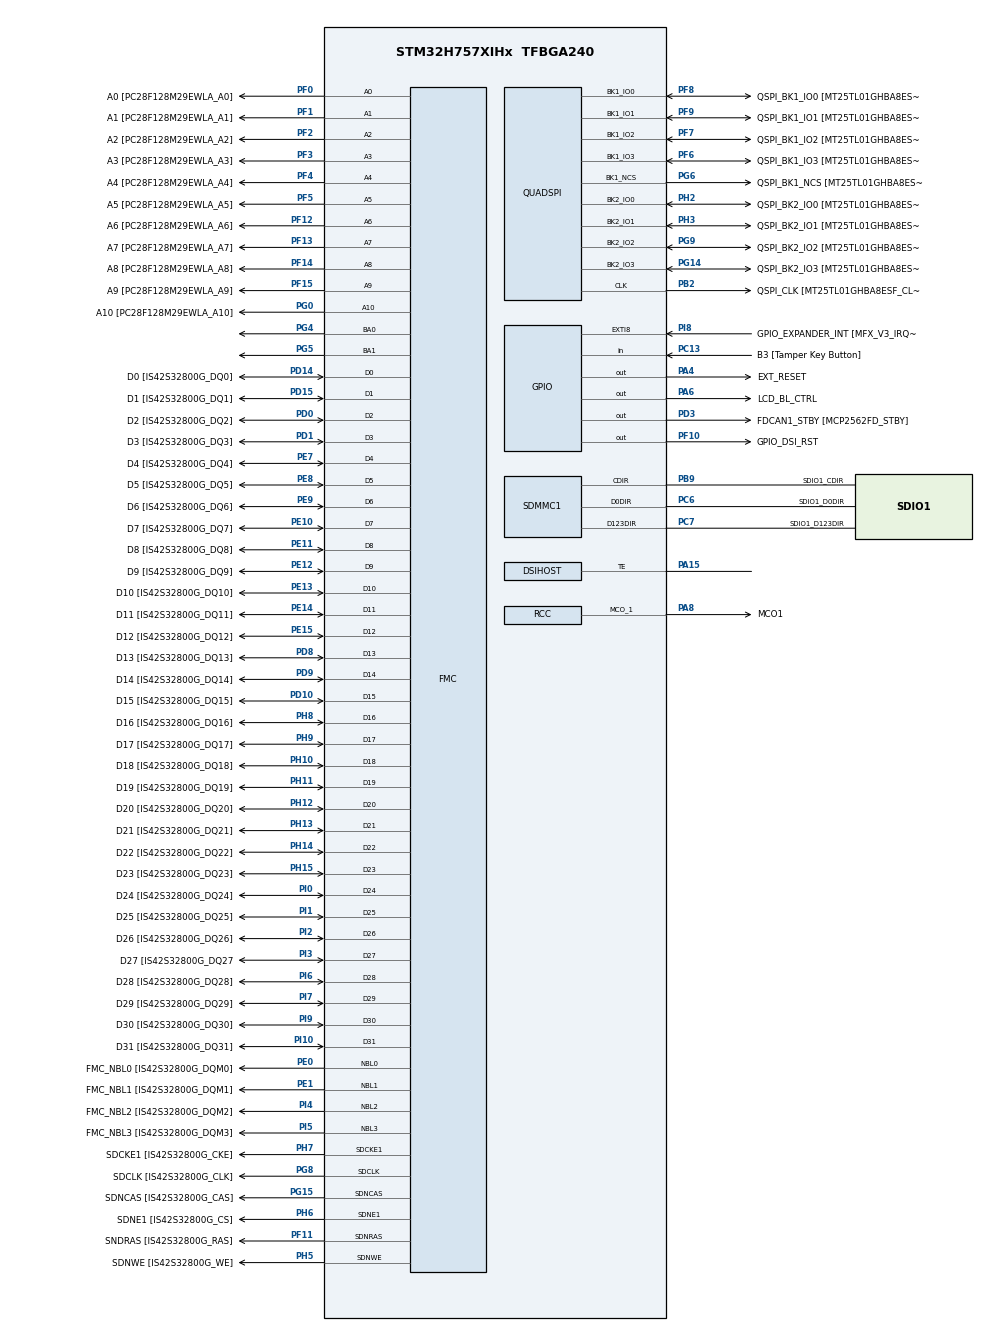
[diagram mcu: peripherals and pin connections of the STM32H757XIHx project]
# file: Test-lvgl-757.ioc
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CortexM4.IPs=FATFS_M4\:I,FREERTOS_M4\:I,IWDG2\:I,RCC,USB_DEVICE_M4\:I,USB_HOST_M4\:I,WWDG2\:I,DMA,BDMA,MDMA,NVIC2\:I,DEBUG,PDM2PCM_M4\:I,PWR,RESMGR_UTILITY,SYS_M4\:I,CORTEX_M4\:I,OPENAMP_M4\:I,VREFBUF
CortexM7.IPs=FATFS_M7\:I,FREERTOS_M7\:I,IWDG1\:I,RCC\:I,USB_DEVICE_M7\:I,USB_HOST_M7\:I,WWDG1\:I,DMA\:I,BDMA\:I,MDMA\:I,NVIC1\:I,FMC\:I,LTDC\:I,DSIHOST\:I,QUADSPI\:I,SYS\:I,CORTEX_M7\:I,DEBUG\:I,PDM2PCM_M7\:I,PWR\:I,RESMGR_UTILITY\:I,OPENAMP_M7\:I,VREFBUF\:I,DMA2D\:I,RTC\:I,TIM2\:I
DMA2D.Mode=DMA2D_R2M
DSIHOST.AcknowledgeRequest=DSI_ACKNOWLEDGE_ENABLE
DSIHOST.AutomaticRefresh=DSI_AR_DISABLE
DSIHOST.CommandSize=800
DSIHOST.LPDcsLongWrite=DSI_LP_DLW_ENABLE
DSIHOST.LPDcsShortReadNoP=DSI_LP_DSR0P_ENABLE
DSIHOST.LPDcsShortWriteNoP=DSI_LP_DSW0P_ENABLE
DSIHOST.LPDcsShortWriteOneP=DSI_LP_DSW1P_ENABLE
DSIHOST.LPGenLongWrite=DSI_LP_GLW_ENABLE
DSIHOST.LPGenShortReadNoP=DSI_LP_GSR0P_ENABLE
DSIHOST.LPGenShortReadOneP=DSI_LP_GSR1P_ENABLE
DSIHOST.LPGenShortReadTwoP=DSI_LP_GSR2P_ENABLE
DSIHOST.LPGenShortWriteNoP=DSI_LP_GSW0P_ENABLE
DSIHOST.LPGenShortWriteOneP=DSI_LP_GSW1P_ENABLE
DSIHOST.LPGenShortWriteTwoP=DSI_LP_GSW2P_ENABLE
DSIHOST.LPMaxReadPacket=DSI_LP_MRDP_ENABLE
DSIHOST.LowPowerReceptionTimeout=0
DSIHOST.NumberOfLanes=DSI_TWO_DATA_LANES
DSIHOST.TEAcknowledgeRequest=DSI_TE_ACKNOWLEDGE_ENABLE
DSI_CKN.Mode=DSIHost_Adapted_TE
DSI_CKN.PinAttribute=CortexM7
DSI_CKN.Signal=DSIHOST_CKN
DSI_CKP.Mode=DSIHost_Adapted_TE
DSI_CKP.PinAttribute=CortexM7
DSI_CKP.Signal=DSIHOST_CKP
DSI_D0N.Mode=DSIHost_Adapted_TE
DSI_D0N.PinAttribute=CortexM7
DSI_D0N.Signal=DSIHOST_D0N
DSI_D0P.Mode=DSIHost_Adapted_TE
DSI_D0P.PinAttribute=CortexM7
DSI_D0P.Signal=DSIHOST_D0P
DSI_D1N.Mode=DSIHost_Adapted_TE
DSI_D1N.PinAttribute=CortexM7
DSI_D1N.Signal=DSIHOST_D1N
DSI_D1P.Mode=DSIHost_Adapted_TE
DSI_D1P.PinAttribute=CortexM7
DSI_D1P.Signal=DSIHOST_D1P
Dma.MEMTOMEM.0.Direction=DMA_MEMORY_TO_MEMORY
Dma.MEMTOMEM.0.EventEnable=DISABLE
Dma.MEMTOMEM.0.FIFOMode=DMA_FIFOMODE_ENABLE
Dma.MEMTOMEM.0.FIFOThreshold=DMA_FIFO_THRESHOLD_1QUARTERFULL
Dma.MEMTOMEM.0.Instance=DMA2_Stream0
Dma.MEMTOMEM.0.MemBurst=DMA_MBURST_SINGLE
Dma.MEMTOMEM.0.MemDataAlignment=DMA_MDATAALIGN_HALFWORD
Dma.MEMTOMEM.0.MemInc=DMA_MINC_ENABLE
Dma.MEMTOMEM.0.Mode=DMA_NORMAL
Dma.MEMTOMEM.0.PeriphBurst=DMA_PBURST_SINGLE
Dma.MEMTOMEM.0.PeriphDataAlignment=DMA_PDATAALIGN_HALFWORD
Dma.MEMTOMEM.0.PeriphInc=DMA_PINC_ENABLE
Dma.MEMTOMEM.0.Polarity=HAL_DMAMUX_REQ_GEN_RISING
Dma.MEMTOMEM.0.Priority=DMA_PRIORITY_HIGH
Dma.MEMTOMEM.0.RequestNumber=1
Dma.MEMTOMEM.0.SignalID=NONE
Dma.MEMTOMEM.0.SyncEnable=DISABLE
Dma.MEMTOMEM.0.SyncPolarity=HAL_DMAMUX_SYNC_NO_EVENT
Dma.MEMTOMEM.0.SyncRequestNumber=1
Dma.MEMTOMEM.0.SyncSignalID=NONE
Dma.Request0=MEMTOMEM
LTDC.ActiveW=800
LTDC.Alpha_L0=255
LTDC.BlendingFactor1_L0=LTDC_BLENDING_FACTOR1_PAxCA
LTDC.BlendingFactor2_L0=LTDC_BLENDING_FACTOR2_PAxCA
LTDC.Blue_L0=20
LTDC.FBStartAdress_L0=0xD0000000
LTDC.Green_L0=40
LTDC.HBP=2
LTDC.HFP=1
LTDC.HSPolarity=LTDC_HSPOLARITY_AH
LTDC.HSync=1
LTDC.ImageHeight_L0=480
LTDC.ImageWidth_L0=800
LTDC.Layers=0
LTDC.PixelFormat_L0=LTDC_PIXEL_FORMAT_RGB565
LTDC.Red_L0=60
LTDC.VFP=1
LTDC.VSPolarity=LTDC_VSPOLARITY_AH
LTDC.VSync=1
LTDC.WindowX1_L0=800
LTDC.WindowY1_L0=480
Mcu.Family=STM32H7
Mcu.Name=STM32H757XIHx
Mcu.Package=TFBGA240
NVIC1.DMA2D_IRQn=true\:0\:0\:false\:false\:true\:true\:true
NVIC1.DSI_IRQn=true\:0\:0\:false\:false\:true\:true\:true
NVIC1.LTDC_IRQn=true\:0\:0\:false\:false\:true\:true\:true
NVIC1.PriorityGroup=NVIC_PRIORITYGROUP_4
NVIC1.TIM2_IRQn=true\:0\:0\:false\:false\:true\:true\:true
NVIC2.PriorityGroup=NVIC_PRIORITYGROUP_4
PA1.GPIO_Label=RMII_REF_CLK [LAN8742A_REFCLK0]
PA1.PinAttribute=CortexM4
PA1.Signal=ETH_REF_CLK
PA11.GPIO_Label=USB_FS2_DM
PA11.PinAttribute=CortexM7
PA11.Signal=USB_OTG_FS_DM
PA12.GPIO_Label=USB_FS2_DP
PA12.PinAttribute=CortexM7
PA12.Signal=USB_OTG_FS_DP
PA15\ (JTDI).Mode=DSIHost_Adapted_TE
PA15\ (JTDI).PinAttribute=CortexM7
PA15\ (JTDI).Signal=DSIHOST_TE
PA2.GPIO_Label=RMII_MDIO [LAN8742A_MDIO]
PA2.PinAttribute=CortexM4
PA2.Signal=ETH_MDIO
PA3.GPIO_Label=ULPI_D0 [USB3320C_D0]
PA3.PinAttribute=CortexM7
PA3.Signal=USB_OTG_HS_ULPI_D0
PA4.GPIO_Label=EXT_RESET
PA4.PinAttribute=Free
PA4.Signal=GPIO_Output
PA5.GPIO_Label=ULPI_CK  [USB3320C_CLKOUT]
PA5.PinAttribute=CortexM7
PA5.Signal=USB_OTG_HS_ULPI_CK
PA6.GPIO_Label=LCD_BL_CTRL
PA6.PinAttribute=Free
PA6.Signal=GPIO_Output
PA7.GPIO_Label=RMII_CRS_DV [LAN8742A_CRS_DV]
PA7.PinAttribute=CortexM4
PA7.Signal=ETH_CRS_DV
PA8.GPIO_Label=MCO1
PA8.Mode=Clock-out-1
PA8.PinAttribute=CortexM7
PA8.Signal=RCC_MCO_1
PA9.GPIO_Label=USB_FS2_VBUS
PA9.PinAttribute=CortexM7
PA9.Signal=USB_OTG_FS_VBUS
PB0.GPIO_Label=ULPI_D1 [USB3320C_D1]
PB0.PinAttribute=CortexM7
PB0.Signal=USB_OTG_HS_ULPI_D1
PB1.GPIO_Label=ULPI_D2 [USB3320C_D2]
PB1.PinAttribute=CortexM7
PB1.Signal=USB_OTG_HS_ULPI_D2
PB10.GPIO_Label=ULPI_D3 [USB3320C_D3]
PB10.PinAttribute=CortexM7
PB10.Signal=USB_OTG_HS_ULPI_D3
PB11.GPIO_Label=ULPI_D4 [USB3320C_D4]
PB11.PinAttribute=CortexM7
PB11.Signal=USB_OTG_HS_ULPI_D4
PB12.GPIO_Label=ULPI_D5 [USB3320C_D5]
PB12.PinAttribute=CortexM7
PB12.Signal=USB_OTG_HS_ULPI_D5
PB13.GPIO_Label=ULPI_D6 [USB3320C_D6]
PB13.PinAttribute=CortexM7
PB13.Signal=USB_OTG_HS_ULPI_D6
PB14.GPIO_Label=RS232_TX [ST3241EBPR_T2IN]
PB14.PinAttribute=CortexM4
PB14.Signal=USART1_TX
PB15.GPIO_Label=RS_232RX [ST3241EBPR_R3OUT]
PB15.PinAttribute=CortexM4
PB15.Signal=USART1_RX
PB2.GPIO_Label=QSPI_CLK [MT25TL01GHBA8ESF_CLK_1]
PB2.Mode=Dual_Bank
PB2.PinAttribute=CortexM7
PB2.Signal=QUADSPI_CLK
PB5.GPIO_Label=ULPI_D7 [USB3320C_D7]
PB5.PinAttribute=CortexM7
PB5.Signal=USB_OTG_HS_ULPI_D7
PB6.GPIO_Label=I2C1_SCL [STM32L152CCT6_I2C_SCL]
PB6.GPIO_Pu=GPIO_PULLUP
PB6.PinAttribute=CortexM4
PB6.Signal=I2C1_SCL
PB7.GPIO_Label=I2C1_SDA [STM32L152CCT6_I2C_SDA]
PB7.GPIO_Pu=GPIO_PULLUP
PB7.PinAttribute=CortexM4
PB7.Signal=I2C1_SDA
PB8.GPIO_Label=SDIO1_CKIN
PB8.PinAttribute=CortexM7
PB8.Signal=SDMMC1_CKIN
PB9.GPIO_Label=SDIO1_CDIR
PB9.Mode=SD_4_bits_Wide_bus_dir_voltage_converter
PB9.PinAttribute=CortexM7
PB9.Signal=SDMMC1_CDIR
PC0.GPIO_Label=ULPI_STP [USB3320C_STP]
PC0.PinAttribute=CortexM7
PC0.Signal=USB_OTG_HS_ULPI_STP
PC1.GPIO_Label=RMII_MDC [LAN8742A_MDC]
PC1.PinAttribute=CortexM4
PC1.Signal=ETH_MDC
PC10.GPIO_Label=SDIO1_D2
PC10.PinAttribute=CortexM7
PC10.Signal=SDMMC1_D2
PC11.GPIO_Label=SDIO1_D3
PC11.PinAttribute=CortexM7
PC11.Signal=SDMMC1_D3
PC12.GPIO_Label=SDIO1_CLK
PC12.PinAttribute=CortexM7
PC12.Signal=SDMMC1_CK
PC13.GPIO_Label=B3 [Tamper Key Button]
PC13.PinAttribute=Free
PC13.Signal=GPIO_Input
PC14-OSC32_IN\ (OSC32_IN).GPIO_Label=OSC32_IN
PC14-OSC32_IN\ (OSC32_IN).Mode=LSE-External-Oscillator
PC14-OSC32_IN\ (OSC32_IN).PinAttribute=CortexM7
PC14-OSC32_IN\ (OSC32_IN).Signal=RCC_OSC32_IN
PC15-OSC32_OUT\ (OSC32_OUT).GPIO_Label=OSC32_OUT
PC15-OSC32_OUT\ (OSC32_OUT).Mode=LSE-External-Oscillator
PC15-OSC32_OUT\ (OSC32_OUT).PinAttribute=CortexM7
PC15-OSC32_OUT\ (OSC32_OUT).Signal=RCC_OSC32_OUT
PC2.GPIO_Label=DFSDM_CLK
PC2.PinAttribute=CortexM7
PC2.Signal=S_CKOUTDFSDM1
PC3.GPIO_Label=DFSM_DAT1
PC3.PinAttribute=CortexM7
PC3.Signal=S_DATAIN1DFSDM1
PC4.GPIO_Label=RMII_RXD0 [LAN8742A_RXD0]
PC4.PinAttribute=CortexM4
PC4.Signal=ETH_RXD0
PC5.GPIO_Label=RMII_RXD1 [LAN8742A_RXD1]
PC5.PinAttribute=CortexM4
PC5.Signal=ETH_RXD1
PC6.GPIO_Label=SDIO1_D0DIR
PC6.Mode=SD_4_bits_Wide_bus_dir_voltage_converter
PC6.PinAttribute=CortexM7
PC6.Signal=SDMMC1_D0DIR
PC7.GPIO_Label=SDIO1_D123DIR
PC7.Mode=SD_4_bits_Wide_bus_dir_voltage_converter
PC7.PinAttribute=CortexM7
PC7.Signal=SDMMC1_D123DIR
PC8.GPIO_Label=SDIO1_D0
PC8.PinAttribute=CortexM7
PC8.Signal=SDMMC1_D0
PC9.GPIO_Label=SDIO1_D1
PC9.PinAttribute=CortexM7
PC9.Signal=SDMMC1_D1
PD0.GPIO_Label=D2 [IS42S32800G_DQ2]
PD0.PinAttribute=CortexM7
PD0.Signal=FMC_D2_DA2
PD1.GPIO_Label=D3 [IS42S32800G_DQ3]
PD1.PinAttribute=CortexM7
PD1.Signal=FMC_D3_DA3
PD10.GPIO_Label=D15 [IS42S32800G_DQ15]
PD10.PinAttribute=CortexM7
PD10.Signal=FMC_D15_DA15
PD11.GPIO_Label=A16 [PC28F128M29EWLA_A16]
PD11.PinAttribute=CortexM7
PD11.Signal=FMC_A16_CLE
PD12.GPIO_Label=A17 [PC28F128M29EWLA_A17]
PD12.PinAttribute=CortexM7
PD12.Signal=FMC_A17_ALE
PD13.GPIO_Label=A18 [PC28F128M29EWLA_A18]
PD13.PinAttribute=CortexM7
PD13.Signal=FMC_A18
PD14.GPIO_Label=D0 [IS42S32800G_DQ0]
PD14.PinAttribute=CortexM7
PD14.Signal=FMC_D0_DA0
PD15.GPIO_Label=D1 [IS42S32800G_DQ1]
PD15.PinAttribute=CortexM7
PD15.Signal=FMC_D1_DA1
PD2.GPIO_Label=SDIO1_CMD
PD2.PinAttribute=CortexM7
PD2.Signal=SDMMC1_CMD
PD3.GPIO_Label=FDCAN1_STBY [MCP2562FD_STBY]
PD3.PinAttribute=Free
PD3.Signal=GPIO_Output
PD4.GPIO_Label=FMC_NOE [IS61WV102416BLL_OE]
PD4.PinAttribute=CortexM7
PD4.Signal=FMC_NOE
PD5.GPIO_Label=FMC_NWE [IS61WV102416BLL_WE]
PD5.PinAttribute=CortexM7
PD5.Signal=FMC_NWE
PD6.GPIO_Label=FMC_NWAIT [PC28F128M29EWLA_RB]
PD6.PinAttribute=CortexM7
PD6.Signal=FMC_NWAIT
PD7.GPIO_Label=FMC_NE1 [PC28F128M29EWLA_E]
PD7.PinAttribute=CortexM7
PD7.Signal=FMC_NE1
PD8.GPIO_Label=D13 [IS42S32800G_DQ13]
PD8.PinAttribute=CortexM7
PD8.Signal=FMC_D13_DA13
PD9.GPIO_Label=D14 [IS42S32800G_DQ14]
PD9.PinAttribute=CortexM7
PD9.Signal=FMC_D14_DA14
PE0.GPIO_Label=FMC_NBL0 [IS42S32800G_DQM0]
PE0.PinAttribute=CortexM7
PE0.Signal=FMC_NBL0
PE1.GPIO_Label=FMC_NBL1 [IS42S32800G_DQM1]
PE1.PinAttribute=CortexM7
PE1.Signal=FMC_NBL1
PE10.GPIO_Label=D7 [IS42S32800G_DQ7]
PE10.PinAttribute=CortexM7
PE10.Signal=FMC_D7_DA7
PE11.GPIO_Label=D8 [IS42S32800G_DQ8]
PE11.PinAttribute=CortexM7
PE11.Signal=FMC_D8_DA8
PE12.GPIO_Label=D9 [IS42S32800G_DQ9]
PE12.PinAttribute=CortexM7
PE12.Signal=FMC_D9_DA9
PE13.GPIO_Label=D10 [IS42S32800G_DQ10]
PE13.PinAttribute=CortexM7
PE13.Signal=FMC_D10_DA10
PE14.GPIO_Label=D11 [IS42S32800G_DQ11]
PE14.PinAttribute=CortexM7
PE14.Signal=FMC_D11_DA11
PE15.GPIO_Label=D12 [IS42S32800G_DQ12]
PE15.PinAttribute=CortexM7
PE15.Signal=FMC_D12_DA12
PE2.GPIO_Label=PDM1_CLK
PE2.PinAttribute=CortexM7
PE2.Signal=SAI4_CK1
PE3.GPIO_Label=SAI1_SDB [WM8994ECS_ADCDAT1]
PE3.PinAttribute=CortexM7
PE3.Signal=SAI1_SD_B
PE4.GPIO_Label=SAI1_FSA [WM8994ECS_LRCLK1]
PE4.PinAttribute=CortexM7
PE4.Signal=SAI1_FS_A
PE5.GPIO_Label=SAI1_SCKA [WM8994ECS_BCK1]
PE5.PinAttribute=CortexM7
PE5.Signal=SAI1_SCK_A
PE6.GPIO_Label=SAI1_SDA [WM8994ECS_DACDAT1]
PE6.PinAttribute=CortexM7
PE6.Signal=SAI1_SD_A
PE7.GPIO_Label=D4 [IS42S32800G_DQ4]
PE7.PinAttribute=CortexM7
PE7.Signal=FMC_D4_DA4
PE8.GPIO_Label=D5 [IS42S32800G_DQ5]
PE8.PinAttribute=CortexM7
PE8.Signal=FMC_D5_DA5
PE9.GPIO_Label=D6 [IS42S32800G_DQ6]
PE9.PinAttribute=CortexM7
PE9.Signal=FMC_D6_DA6
PF0.GPIO_Label=A0 [PC28F128M29EWLA_A0]
PF0.PinAttribute=CortexM7
PF0.Signal=FMC_A0
PF1.GPIO_Label=A1 [PC28F128M29EWLA_A1]
PF1.PinAttribute=CortexM7
PF1.Signal=FMC_A1
PF10.GPIO_Label=GPIO_DSI_RST
PF10.PinAttribute=Free
PF10.Signal=GPIO_Output
PF11.GPIO_Label=SNDRAS [IS42S32800G_RAS]
PF11.PinAttribute=CortexM7
PF11.Signal=FMC_SDNRAS
PF12.GPIO_Label=A6 [PC28F128M29EWLA_A6]
PF12.PinAttribute=CortexM7
PF12.Signal=FMC_A6
PF13.GPIO_Label=A7 [PC28F128M29EWLA_A7]
PF13.PinAttribute=CortexM7
PF13.Signal=FMC_A7
PF14.GPIO_Label=A8 [PC28F128M29EWLA_A8]
PF14.PinAttribute=CortexM7
PF14.Signal=FMC_A8
PF15.GPIO_Label=A9 [PC28F128M29EWLA_A9]
PF15.PinAttribute=CortexM7
PF15.Signal=FMC_A9
PF2.GPIO_Label=A2 [PC28F128M29EWLA_A2]
PF2.PinAttribute=CortexM7
PF2.Signal=FMC_A2
PF3.GPIO_Label=A3 [PC28F128M29EWLA_A3]
PF3.PinAttribute=CortexM7
PF3.Signal=FMC_A3
PF4.GPIO_Label=A4 [PC28F128M29EWLA_A4]
PF4.PinAttribute=CortexM7
PF4.Signal=FMC_A4
PF5.GPIO_Label=A5 [PC28F128M29EWLA_A5]
PF5.PinAttribute=CortexM7
PF5.Signal=FMC_A5
PF6.GPIO_Label=QSPI_BK1_IO3 [MT25TL01GHBA8ESF_DQ3]
PF6.Mode=Dual_Bank
PF6.PinAttribute=CortexM7
PF6.Signal=QUADSPI_BK1_IO3
PF7.GPIO_Label=QSPI_BK1_IO2 [MT25TL01GHBA8ESF_DQ2]
PF7.Mode=Dual_Bank
PF7.PinAttribute=CortexM7
PF7.Signal=QUADSPI_BK1_IO2
PF8.GPIO_Label=QSPI_BK1_IO0 [MT25TL01GHBA8ESF_DQ0]
PF8.Mode=Dual_Bank
PF8.PinAttribute=CortexM7
PF8.Signal=QUADSPI_BK1_IO0
PF9.GPIO_Label=QSPI_BK1_IO1 [MT25TL01GHBA8ESF_DQ1]
PF9.Mode=Dual_Bank
PF9.PinAttribute=CortexM7
PF9.Signal=QUADSPI_BK1_IO1
PG0.GPIO_Label=A10 [PC28F128M29EWLA_A10]
PG0.PinAttribute=CortexM7
PG0.Signal=FMC_A10
PG1.GPIO_Label=A11 [PC28F128M29EWLA_A11]
PG1.PinAttribute=CortexM7
PG1.Signal=FMC_A11
PG10.GPIO_Label=FMC_NE3 [IS61WV102416BLL_CE]
PG10.PinAttribute=CortexM7
PG10.Signal=FMC_NE3
PG11.GPIO_Label=RMII_TX_EN [LAN8742A_TXEN]
PG11.PinAttribute=CortexM4
PG11.Signal=ETH_TX_EN
PG12.GPIO_Label=RMII_TXD1 [LAN8742A_TXD1]
PG12.PinAttribute=CortexM4
PG12.Signal=ETH_TXD1
PG13.GPIO_Label=RMII_TXD0 [LAN8742A_TXD0]
PG13.PinAttribute=CortexM4
PG13.Signal=ETH_TXD0
PG14.GPIO_Label=QSPI_BK2_IO3 [MT25TL01GHBA8ESF_DQ7]
PG14.Mode=Dual_Bank
PG14.PinAttribute=CortexM7
PG14.Signal=QUADSPI_BK2_IO3
PG15.GPIO_Label=SDNCAS [IS42S32800G_CAS]
PG15.PinAttribute=CortexM7
PG15.Signal=FMC_SDNCAS
PG2.GPIO_Label=A12 [PC28F128M29EWLA_A12]
PG2.PinAttribute=CortexM7
PG2.Signal=FMC_A12
PG3.GPIO_Label=A13 [PC28F128M29EWLA_A13]
PG3.PinAttribute=CortexM7
PG3.Signal=FMC_A13
PG4.PinAttribute=CortexM7
PG4.Signal=FMC_A14_BA0
PG5.PinAttribute=CortexM7
PG5.Signal=FMC_A15_BA1
PG6.GPIO_Label=QSPI_BK1_NCS [MT25TL01GHBA8ESF_CS]
PG6.Mode=Enable Chip Select 1 for both banks
PG6.PinAttribute=CortexM7
PG6.Signal=QUADSPI_BK1_NCS
PG7.GPIO_Label=SAI1_MCLKA [WM8994ECS_MCLK1]
PG7.PinAttribute=CortexM7
PG7.Signal=SAI1_MCLK_A
PG8.GPIO_Label=SDCLK [IS42S32800G_CLK]
PG8.PinAttribute=CortexM7
PG8.Signal=FMC_SDCLK
PG9.GPIO_Label=QSPI_BK2_IO2 [MT25TL01GHBA8ESF_DQ6]
PG9.Mode=Dual_Bank
PG9.PinAttribute=CortexM7
PG9.Signal=QUADSPI_BK2_IO2
PH0-OSC_IN\ (PH0).GPIO_Label=OSC_IN
PH0-OSC_IN\ (PH0).Mode=HSE-External-Oscillator
PH0-OSC_IN\ (PH0).PinAttribute=CortexM7
PH0-OSC_IN\ (PH0).Signal=RCC_OSC_IN
PH1-OSC_OUT\ (PH1).GPIO_Label=OSC_OUT
PH1-OSC_OUT\ (PH1).Mode=HSE-External-Oscillator
PH1-OSC_OUT\ (PH1).PinAttribute=CortexM7
PH1-OSC_OUT\ (PH1).Signal=RCC_OSC_OUT
PH10.GPIO_Label=D18 [IS42S32800G_DQ18]
PH10.PinAttribute=CortexM7
PH10.Signal=FMC_D18
PH11.GPIO_Label=D19 [IS42S32800G_DQ19]
PH11.PinAttribute=CortexM7
PH11.Signal=FMC_D19
PH12.GPIO_Label=D20 [IS42S32800G_DQ20]
PH12.PinAttribute=CortexM7
PH12.Signal=FMC_D20
PH13.GPIO_Label=D21 [IS42S32800G_DQ21]
PH13.PinAttribute=CortexM7
PH13.Signal=FMC_D21
PH14.GPIO_Label=D22 [IS42S32800G_DQ22]
PH14.PinAttribute=CortexM7
PH14.Signal=FMC_D22
PH15.GPIO_Label=D23 [IS42S32800G_DQ23]
PH15.PinAttribute=CortexM7
PH15.Signal=FMC_D23
PH2.GPIO_Label=QSPI_BK2_IO0 [MT25TL01GHBA8ESF_DQ4]
PH2.Mode=Dual_Bank
PH2.PinAttribute=CortexM7
PH2.Signal=QUADSPI_BK2_IO0
PH3.GPIO_Label=QSPI_BK2_IO1 [MT25TL01GHBA8ESF_DQ5]
PH3.Mode=Dual_Bank
PH3.PinAttribute=CortexM7
PH3.Signal=QUADSPI_BK2_IO1
PH4.GPIO_Label=ULPI_NXT [USB3320C_NXT]
PH4.PinAttribute=CortexM7
PH4.Signal=USB_OTG_HS_ULPI_NXT
PH5.GPIO_Label=SDNWE [IS42S32800G_WE]
PH5.PinAttribute=CortexM7
PH5.Signal=FMC_SDNWE
PH6.GPIO_Label=SDNE1 [IS42S32800G_CS]
PH6.Mode=SdramChipSelect2_1
PH6.PinAttribute=CortexM7
PH6.Signal=FMC_SDNE1
PH7.GPIO_Label=SDCKE1 [IS42S32800G_CKE]
PH7.Mode=SdramChipSelect2_1
PH7.PinAttribute=CortexM7
PH7.Signal=FMC_SDCKE1
PH8.GPIO_Label=D16 [IS42S32800G_DQ16]
PH8.PinAttribute=CortexM7
PH8.Signal=FMC_D16
PH9.GPIO_Label=D17 [IS42S32800G_DQ17]
PH9.PinAttribute=CortexM7
PH9.Signal=FMC_D17
PI0.GPIO_Label=D24 [IS42S32800G_DQ24]
PI0.PinAttribute=CortexM7
PI0.Signal=FMC_D24
PI1.GPIO_Label=D25 [IS42S32800G_DQ25]
PI1.PinAttribute=CortexM7
PI1.Signal=FMC_D25
PI10.GPIO_Label=D31 [IS42S32800G_DQ31]
PI10.PinAttribute=CortexM7
PI10.Signal=FMC_D31
PI11.GPIO_Label=ULPI_DIR [USB3320C_DIR]
PI11.PinAttribute=CortexM7
PI11.Signal=USB_OTG_HS_ULPI_DIR
PI2.GPIO_Label=D26 [IS42S32800G_DQ26]
PI2.PinAttribute=CortexM7
PI2.Signal=FMC_D26
PI3.GPIO_Label=D27 [IS42S32800G_DQ27
PI3.PinAttribute=CortexM7
PI3.Signal=FMC_D27
PI4.GPIO_Label=FMC_NBL2 [IS42S32800G_DQM2]
PI4.PinAttribute=CortexM7
PI4.Signal=FMC_NBL2
PI5.GPIO_Label=FMC_NBL3 [IS42S32800G_DQM3]
PI5.PinAttribute=CortexM7
PI5.Signal=FMC_NBL3
PI6.GPIO_Label=D28 [IS42S32800G_DQ28]
PI6.PinAttribute=CortexM7
PI6.Signal=FMC_D28
PI7.GPIO_Label=D29 [IS42S32800G_DQ29]
PI7.PinAttribute=CortexM7
PI7.Signal=FMC_D29
PI8.GPIO_Label=GPIO_EXPANDER_INT [MFX_V3_IRQOUT]
PI8.PinAttribute=Free
PI8.Signal=GPXTI8
PI9.GPIO_Label=D30 [IS42S32800G_DQ30]
PI9.PinAttribute=CortexM7
PI9.Signal=FMC_D30
ProjectManager.HeapSize=M4-0x200,M7-0x200
ProjectManager.StackSize=M4-0x400,M7-0x400
ProjectManager.TargetToolchain=STM32CubeIDE
QUADSPI.ClockPrescaler=3
RCC.ADCFreq_Value=50537109.375
RCC.APB1Freq_Value=100000000
RCC.APB2Freq_Value=100000000
RCC.APB3Freq_Value=100000000
RCC.APB4Freq_Value=100000000
RCC.CortexFreq_Value=400000000
RCC.D1PPRE=RCC_APB3_DIV2
RCC.D2PPRE1=RCC_APB1_DIV2
RCC.D2PPRE2=RCC_APB2_DIV2
RCC.D3PPRE=RCC_APB4_DIV2
RCC.DIVM1=5
RCC.DIVM3=5
RCC.DIVN1=160
RCC.DIVN3=161
RCC.DIVR3=21
RCC.DSITX_Div=2
RCC.HCLKFreq_Value=200000000
RCC.HPRE=RCC_HCLK_DIV2
RCC.PLL2FRACN=3072
RCC.PLL3FRACN=0
RCC.PLLDSINDIV=10
RCC.PLLFRACN=0
RCC.PLLSourceVirtual=RCC_PLLSOURCE_HSE
RCC.PWR_Regulator_Voltage_Scale=PWR_REGULATOR_VOLTAGE_SCALE1
RCC.RTCClockSelection=RCC_RTCCLKSOURCE_LSE
RCC.SYSCLKFreq_VALUE=400000000
RCC.SYSCLKSource=RCC_SYSCLKSOURCE_PLLCLK
RCC.SupplySource=PWR_DIRECT_SMPS_SUPPLY
RCC.USBCLockSelection=RCC_USBCLKSOURCE_HSI48
RCC.USBFreq_Value=48000000
SH.FMC_A0.0=FMC_A0
SH.FMC_A0.1=FMC_A0
SH.FMC_A0.2=FMC_A0,11b-sda1
SH.FMC_A1.0=FMC_A1
SH.FMC_A1.1=FMC_A1
SH.FMC_A1.2=FMC_A1,11b-sda1
SH.FMC_A10.0=FMC_A10
SH.FMC_A10.1=FMC_A10
SH.FMC_A10.2=FMC_A10,11b-sda1
SH.FMC_A11.0=FMC_A11
SH.FMC_A11.1=FMC_A11
SH.FMC_A12.0=FMC_A12
SH.FMC_A12.1=FMC_A12
SH.FMC_A13.0=FMC_A13
SH.FMC_A13.1=FMC_A13
SH.FMC_A14_BA0.0=FMC_A14
SH.FMC_A14_BA0.1=FMC_A14
SH.FMC_A14_BA0.2=FMC_BA0,FourSdramBanks1
SH.FMC_A15_BA1.0=FMC_A15
SH.FMC_A15_BA1.1=FMC_A15
SH.FMC_A15_BA1.2=FMC_BA1,FourSdramBanks1
SH.FMC_A16_CLE.0=FMC_A16
SH.FMC_A16_CLE.1=FMC_A16
SH.FMC_A17_ALE.0=FMC_A17
SH.FMC_A17_ALE.1=FMC_A17
SH.FMC_A18.0=FMC_A18
SH.FMC_A18.1=FMC_A18
SH.FMC_A2.0=FMC_A2
SH.FMC_A2.1=FMC_A2
SH.FMC_A2.2=FMC_A2,11b-sda1
SH.FMC_A3.0=FMC_A3
SH.FMC_A3.1=FMC_A3
SH.FMC_A3.2=FMC_A3,11b-sda1
SH.FMC_A4.0=FMC_A4
SH.FMC_A4.1=FMC_A4
SH.FMC_A4.2=FMC_A4,11b-sda1
SH.FMC_A5.0=FMC_A5
SH.FMC_A5.1=FMC_A5
SH.FMC_A5.2=FMC_A5,11b-sda1
SH.FMC_A6.0=FMC_A6
SH.FMC_A6.1=FMC_A6
SH.FMC_A6.2=FMC_A6,11b-sda1
SH.FMC_A7.0=FMC_A7
SH.FMC_A7.1=FMC_A7
SH.FMC_A7.2=FMC_A7,11b-sda1
SH.FMC_A8.0=FMC_A8
SH.FMC_A8.1=FMC_A8
SH.FMC_A8.2=FMC_A8,11b-sda1
SH.FMC_A9.0=FMC_A9
SH.FMC_A9.1=FMC_A9
SH.FMC_A9.2=FMC_A9,11b-sda1
SH.FMC_D0_DA0.0=FMC_D0
SH.FMC_D0_DA0.1=FMC_D0
SH.FMC_D0_DA0.2=FMC_D0,sd-32b-d1
SH.FMC_D10_DA10.0=FMC_D10
SH.FMC_D10_DA10.1=FMC_D10
SH.FMC_D10_DA10.2=FMC_D10,sd-32b-d1
SH.FMC_D11_DA11.0=FMC_D11
SH.FMC_D11_DA11.1=FMC_D11
SH.FMC_D11_DA11.2=FMC_D11,sd-32b-d1
SH.FMC_D12_DA12.0=FMC_D12
SH.FMC_D12_DA12.1=FMC_D12
SH.FMC_D12_DA12.2=FMC_D12,sd-32b-d1
SH.FMC_D13_DA13.0=FMC_D13
SH.FMC_D13_DA13.1=FMC_D13
SH.FMC_D13_DA13.2=FMC_D13,sd-32b-d1
SH.FMC_D14_DA14.0=FMC_D14
SH.FMC_D14_DA14.1=FMC_D14
SH.FMC_D14_DA14.2=FMC_D14,sd-32b-d1
SH.FMC_D15_DA15.0=FMC_D15
SH.FMC_D15_DA15.1=FMC_D15
SH.FMC_D15_DA15.2=FMC_D15,sd-32b-d1
SH.FMC_D16.0=FMC_D16,sd-32b-d1
SH.FMC_D17.0=FMC_D17,sd-32b-d1
SH.FMC_D18.0=FMC_D18,sd-32b-d1
SH.FMC_D19.0=FMC_D19,sd-32b-d1
SH.FMC_D1_DA1.0=FMC_D1
SH.FMC_D1_DA1.1=FMC_D1
SH.FMC_D1_DA1.2=FMC_D1,sd-32b-d1
SH.FMC_D20.0=FMC_D20,sd-32b-d1
SH.FMC_D21.0=FMC_D21,sd-32b-d1
SH.FMC_D22.0=FMC_D22,sd-32b-d1
SH.FMC_D23.0=FMC_D23,sd-32b-d1
SH.FMC_D24.0=FMC_D24,sd-32b-d1
SH.FMC_D25.0=FMC_D25,sd-32b-d1
SH.FMC_D26.0=FMC_D26,sd-32b-d1
SH.FMC_D27.0=FMC_D27,sd-32b-d1
SH.FMC_D28.0=FMC_D28,sd-32b-d1
SH.FMC_D29.0=FMC_D29,sd-32b-d1
SH.FMC_D2_DA2.0=FMC_D2
SH.FMC_D2_DA2.1=FMC_D2
SH.FMC_D2_DA2.2=FMC_D2,sd-32b-d1
SH.FMC_D30.0=FMC_D30,sd-32b-d1
SH.FMC_D31.0=FMC_D31,sd-32b-d1
SH.FMC_D3_DA3.0=FMC_D3
SH.FMC_D3_DA3.1=FMC_D3
SH.FMC_D3_DA3.2=FMC_D3,sd-32b-d1
SH.FMC_D4_DA4.0=FMC_D4
SH.FMC_D4_DA4.1=FMC_D4
SH.FMC_D4_DA4.2=FMC_D4,sd-32b-d1
SH.FMC_D5_DA5.0=FMC_D5
SH.FMC_D5_DA5.1=FMC_D5
SH.FMC_D5_DA5.2=FMC_D5,sd-32b-d1
SH.FMC_D6_DA6.0=FMC_D6
SH.FMC_D6_DA6.1=FMC_D6
SH.FMC_D6_DA6.2=FMC_D6,sd-32b-d1
SH.FMC_D7_DA7.0=FMC_D7
SH.FMC_D7_DA7.1=FMC_D7
SH.FMC_D7_DA7.2=FMC_D7,sd-32b-d1
SH.FMC_D8_DA8.0=FMC_D8
SH.FMC_D8_DA8.1=FMC_D8
SH.FMC_D8_DA8.2=FMC_D8,sd-32b-d1
SH.FMC_D9_DA9.0=FMC_D9
SH.FMC_D9_DA9.1=FMC_D9
SH.FMC_D9_DA9.2=FMC_D9,sd-32b-d1
SH.FMC_NBL0.0=FMC_NBL0
SH.FMC_NBL0.1=FMC_NBL0,Sd4ByteEnable1
SH.FMC_NBL1.0=FMC_NBL1
SH.FMC_NBL1.1=FMC_NBL1,Sd4ByteEnable1
SH.FMC_NBL2.0=FMC_NBL2,Sd4ByteEnable1
SH.FMC_NBL3.0=FMC_NBL3,Sd4ByteEnable1
SH.FMC_NOE.0=FMC_NOE
SH.FMC_NOE.1=FMC_NOE
SH.FMC_NWAIT.0=FMC_NWAIT
SH.FMC_NWAIT.1=FMC_NWAIT
SH.FMC_NWE.0=FMC_NWE
SH.FMC_NWE.1=FMC_NWE
SH.FMC_SDCLK.0=FMC_SDCLK,11b-sda1
SH.FMC_SDNCAS.0=FMC_SDNCAS,11b-sda1
SH.FMC_SDNRAS.0=FMC_SDNRAS,11b-sda1
SH.FMC_SDNWE.0=FMC_SDNWE,11b-sda1
SH.S_CKOUTDFSDM1.0=DFSDM1_CKOUT
SH.S_DATAIN1DFSDM1.0=DFSDM1_DATIN1
TIM2.AutoReloadPreload=TIM_AUTORELOAD_PRELOAD_ENABLE
TIM2.Period=72
TIM2.Prescaler=1000
VP_DMA2D_VS_DMA2D.Mode=DMA2D_Activate
VP_LTDC_DSIMode.Mode=RGB565
VP_RTC_VS_RTC_Activate.Mode=RTC_Enabled
VP_SYS_M4_VS_Systick.Mode=SysTick
VP_TIM2_VS_ClockSourceINT.Mode=Internal
board=STM32H757I-EVAL

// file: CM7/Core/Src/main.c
/* USER CODE BEGIN Header */
/**
  ******************************************************************************
  * @file           : main.c
  * @brief          : Main program body
  ******************************************************************************
  * @attention
  *
  * <h2><center>&copy; Copyright (c) 2021 STMicroelectronics.
  * All rights reserved.</center></h2>
  *
  * This software component is licensed by ST under BSD 3-Clause license,
  * the "License"; You may not use this file except in compliance with the
  * License. You may obtain a copy of the License at:
  *                        opensource.org/licenses/BSD-3-Clause
  *
  ******************************************************************************
  */
/* USER CODE END Header */
#include "main.h"

/* USER CODE BEGIN Includes */
#include "../lvgl/lvgl.h"
#include "../lvgl/examples/lv_examples.h"
#include "../lv_demos/lv_demo.h"

/* USER CODE END Includes */

/* USER CODE BEGIN PTD */
TIM_HandleTypeDef htim2;

/* USER CODE END PTD */

/* USER CODE BEGIN PD */

#ifndef HSEM_ID_0
#define HSEM_ID_0 (0U) /* HW semaphore 0*/
#endif
/* USER CODE END PD */

DMA2D_HandleTypeDef hdma2d;

DSI_HandleTypeDef hdsi;

LTDC_HandleTypeDef hltdc;

QSPI_HandleTypeDef hqspi;

RTC_HandleTypeDef hrtc;

TIM_HandleTypeDef htim2;

DMA_HandleTypeDef hdma_memtomem_dma2_stream0;
SDRAM_HandleTypeDef hsdram1;

void SystemClock_Config(void);
static void MX_GPIO_Init(void);
static void MX_DSIHOST_DSI_Init(void);
static void MX_FMC_Init(void);
static void MX_LTDC_Init(void);
static void MX_QUADSPI_Init(void);
static void MX_DMA_Init(void);
static void MX_DMA2D_Init(void);
static void MX_RTC_Init(void);
static void MX_TIM2_Init(void);

/* USER CODE BEGIN 0 */

typedef struct {
	uint8_t Red;
	uint8_t Green;
	uint8_t Blue;
}__colr;

uint8_t pColLeft[] = { 0x00, 0x00, 0x01, 0x8f }; /*   0 -> 399 */
uint8_t pColRight[] = { 0x01, 0x90, 0x03, 0x1F }; /* 400 -> 799 */

/* USER CODE END 0 */

int main(void)
{
/* USER CODE BEGIN Boot_Mode_Sequence_0 */
  int32_t timeout;
/* USER CODE END Boot_Mode_Sequence_0 */

/* USER CODE BEGIN Boot_Mode_Sequence_1 */
  /* Wait until CPU2 boots and enters in stop mode or timeout*/
  timeout = 0xFFFF;
  while((__HAL_RCC_GET_FLAG(RCC_FLAG_D2CKRDY) != RESET) && (timeout-- > 0));
  if ( timeout < 0 )
  {
  Error_Handler();
  }
/* USER CODE END Boot_Mode_Sequence_1 */
  /* MCU Configuration--------------------------------------------------------*/

  /* Reset of all peripherals, Initializes the Flash interface and the Systick. */
  HAL_Init();

  /* Configure the system clock */
  SystemClock_Config();
/* USER CODE BEGIN Boot_Mode_Sequence_2 */
/* When system initialization is finished, Cortex-M7 will release Cortex-M4 by means of
HSEM notification */
/*HW semaphore Clock enable*/
__HAL_RCC_HSEM_CLK_ENABLE();
/*Take HSEM */
HAL_HSEM_FastTake(HSEM_ID_0);
/*Release HSEM in order to notify the CPU2(CM4)*/
HAL_HSEM_Release(HSEM_ID_0,0);
/* wait until CPU2 wakes up from stop mode */
timeout = 0xFFFF;
while((__HAL_RCC_GET_FLAG(RCC_FLAG_D2CKRDY) == RESET) && (timeout-- > 0));
if ( timeout < 0 )
{
Error_Handler();
}
/* USER CODE END Boot_Mode_Sequence_2 */

  /* Initialize all configured peripherals */
  MX_GPIO_Init();
  MX_DSIHOST_DSI_Init();
  MX_FMC_Init();
  MX_LTDC_Init();
  MX_QUADSPI_Init();
  MX_DMA_Init();
  MX_DMA2D_Init();
  MX_RTC_Init();
  MX_TIM2_Init();
  /* USER CODE BEGIN 2 */

  HAL_TIM_Base_Start_IT(&htim2);

  lv_init();

  tft_init();

  touchpad_init();

  lv_demo_widgets();

  /* USER CODE END 2 */

  /* Infinite loop */
  while (1)
  {
	lv_task_handler();
	HAL_Delay(5);
  }
}

void SystemClock_Config(void)
{
  RCC_OscInitTypeDef RCC_OscInitStruct = {0};
  RCC_ClkInitTypeDef RCC_ClkInitStruct = {0};

  /** Supply configuration update enable
  */
  HAL_PWREx_ConfigSupply(PWR_DIRECT_SMPS_SUPPLY);
  /** Configure the main internal regulator output voltage
  */
  __HAL_PWR_VOLTAGESCALING_CONFIG(PWR_REGULATOR_VOLTAGE_SCALE1);

  while(!__HAL_PWR_GET_FLAG(PWR_FLAG_VOSRDY)) {}
  /** Configure LSE Drive Capability
  */
  HAL_PWR_EnableBkUpAccess();
  __HAL_RCC_LSEDRIVE_CONFIG(RCC_LSEDRIVE_LOW);
  /** Macro to configure the PLL clock source
  */
  __HAL_RCC_PLL_PLLSOURCE_CONFIG(RCC_PLLSOURCE_HSE);
  /** Initializes the RCC Oscillators according to the specified parameters
  * in the RCC_OscInitTypeDef structure.
  */
  RCC_OscInitStruct.OscillatorType = RCC_OSCILLATORTYPE_HSI|RCC_OSCILLATORTYPE_HSE
                              |RCC_OSCILLATORTYPE_LSE;
  RCC_OscInitStruct.HSEState = RCC_HSE_ON;
  RCC_OscInitStruct.LSEState = RCC_LSE_ON;
  RCC_OscInitStruct.HSIState = RCC_HSI_DIV1;
  RCC_OscInitStruct.HSICalibrationValue = RCC_HSICALIBRATION_DEFAULT;
  RCC_OscInitStruct.PLL.PLLState = RCC_PLL_ON;
  RCC_OscInitStruct.PLL.PLLSource = RCC_PLLSOURCE_HSE;
  RCC_OscInitStruct.PLL.PLLM = 5;
  RCC_OscInitStruct.PLL.PLLN = 160;
  RCC_OscInitStruct.PLL.PLLP = 2;
  RCC_OscInitStruct.PLL.PLLQ = 2;
  RCC_OscInitStruct.PLL.PLLR = 2;
  RCC_OscInitStruct.PLL.PLLRGE = RCC_PLL1VCIRANGE_2;
  RCC_OscInitStruct.PLL.PLLVCOSEL = RCC_PLL1VCOWIDE;
  RCC_OscInitStruct.PLL.PLLFRACN = 0;
  if (HAL_RCC_OscConfig(&RCC_OscInitStruct) != HAL_OK)
  {
    Error_Handler();
  }
  /** Initializes the CPU, AHB and APB buses clocks
  */
  RCC_ClkInitStruct.ClockType = RCC_CLOCKTYPE_HCLK|RCC_CLOCKTYPE_SYSCLK
                              |RCC_CLOCKTYPE_PCLK1|RCC_CLOCKTYPE_PCLK2
                              |RCC_CLOCKTYPE_D3PCLK1|RCC_CLOCKTYPE_D1PCLK1;
  RCC_ClkInitStruct.SYSCLKSource = RCC_SYSCLKSOURCE_PLLCLK;
  RCC_ClkInitStruct.SYSCLKDivider = RCC_SYSCLK_DIV1;
  RCC_ClkInitStruct.AHBCLKDivider = RCC_HCLK_DIV2;
  RCC_ClkInitStruct.APB3CLKDivider = RCC_APB3_DIV2;
  RCC_ClkInitStruct.APB1CLKDivider = RCC_APB1_DIV2;
  RCC_ClkInitStruct.APB2CLKDivider = RCC_APB2_DIV2;
  RCC_ClkInitStruct.APB4CLKDivider = RCC_APB4_DIV2;

  if (HAL_RCC_ClockConfig(&RCC_ClkInitStruct, FLASH_LATENCY_2) != HAL_OK)
  {
    Error_Handler();
  }
  HAL_RCC_MCOConfig(RCC_MCO1, RCC_MCO1SOURCE_HSI, RCC_MCODIV_1);
}

static void MX_DMA2D_Init(void)
{

  hdma2d.Instance = DMA2D;
  hdma2d.Init.Mode = DMA2D_R2M;
  hdma2d.Init.ColorMode = DMA2D_OUTPUT_ARGB8888;
  hdma2d.Init.OutputOffset = 0;
  if (HAL_DMA2D_Init(&hdma2d) != HAL_OK)
  {
    Error_Handler();
  }

}

static void MX_DSIHOST_DSI_Init(void)
{

  DSI_PLLInitTypeDef PLLInit = {0};
  DSI_HOST_TimeoutTypeDef HostTimeouts = {0};
  DSI_PHY_TimerTypeDef PhyTimings = {0};
  DSI_LPCmdTypeDef LPCmd = {0};
  DSI_CmdCfgTypeDef CmdCfg = {0};

  hdsi.Instance = DSI;
  hdsi.Init.AutomaticClockLaneControl = DSI_AUTO_CLK_LANE_CTRL_DISABLE;
  hdsi.Init.TXEscapeCkdiv = 2;
  hdsi.Init.NumberOfLanes = DSI_TWO_DATA_LANES;
  PLLInit.PLLNDIV = 10;
  PLLInit.PLLIDF = DSI_PLL_IN_DIV1;
  PLLInit.PLLODF = DSI_PLL_OUT_DIV1;
  if (HAL_DSI_Init(&hdsi, &PLLInit) != HAL_OK)
  {
    Error_Handler();
  }
  HostTimeouts.TimeoutCkdiv = 1;
  HostTimeouts.HighSpeedTransmissionTimeout = 0;
  HostTimeouts.LowPowerReceptionTimeout = 0;
  HostTimeouts.HighSpeedReadTimeout = 0;
  HostTimeouts.LowPowerReadTimeout = 0;
  HostTimeouts.HighSpeedWriteTimeout = 0;
  HostTimeouts.HighSpeedWritePrespMode = DSI_HS_PM_DISABLE;
  HostTimeouts.LowPowerWriteTimeout = 0;
  HostTimeouts.BTATimeout = 0;
  if (HAL_DSI_ConfigHostTimeouts(&hdsi, &HostTimeouts) != HAL_OK)
  {
    Error_Handler();
  }
  PhyTimings.ClockLaneHS2LPTime = 20;
  PhyTimings.ClockLaneLP2HSTime = 18;
  PhyTimings.DataLaneHS2LPTime = 10;
  PhyTimings.DataLaneLP2HSTime = 13;
  PhyTimings.DataLaneMaxReadTime = 0;
  PhyTimings.StopWaitTime = 0;
  if (HAL_DSI_ConfigPhyTimer(&hdsi, &PhyTimings) != HAL_OK)
  {
    Error_Handler();
  }
  if (HAL_DSI_ConfigFlowControl(&hdsi, DSI_FLOW_CONTROL_BTA) != HAL_OK)
  {
    Error_Handler();
  }
  if (HAL_DSI_SetLowPowerRXFilter(&hdsi, 10000) != HAL_OK)
  {
    Error_Handler();
  }
  if (HAL_DSI_ConfigErrorMonitor(&hdsi, HAL_DSI_ERROR_NONE) != HAL_OK)
  {
    Error_Handler();
  }
  LPCmd.LPGenShortWriteNoP = DSI_LP_GSW0P_ENABLE;
  LPCmd.LPGenShortWriteOneP = DSI_LP_GSW1P_ENABLE;
  LPCmd.LPGenShortWriteTwoP = DSI_LP_GSW2P_ENABLE;
  LPCmd.LPGenShortReadNoP = DSI_LP_GSR0P_ENABLE;
  LPCmd.LPGenShortReadOneP = DSI_LP_GSR1P_ENABLE;
  LPCmd.LPGenShortReadTwoP = DSI_LP_GSR2P_ENABLE;
  LPCmd.LPGenLongWrite = DSI_LP_GLW_ENABLE;
  LPCmd.LPDcsShortWriteNoP = DSI_LP_DSW0P_ENABLE;
  LPCmd.LPDcsShortWriteOneP = DSI_LP_DSW1P_ENABLE;
  LPCmd.LPDcsShortReadNoP = DSI_LP_DSR0P_ENABLE;
  LPCmd.LPDcsLongWrite = DSI_LP_DLW_ENABLE;
  LPCmd.LPMaxReadPacket = DSI_LP_MRDP_ENABLE;
  LPCmd.AcknowledgeRequest = DSI_ACKNOWLEDGE_ENABLE;
  if (HAL_DSI_ConfigCommand(&hdsi, &LPCmd) != HAL_OK)
  {
    Error_Handler();
  }
  CmdCfg.VirtualChannelID = 0;
  CmdCfg.ColorCoding = DSI_RGB565;
  CmdCfg.CommandSize = 800;
  CmdCfg.TearingEffectSource = DSI_TE_EXTERNAL;
  CmdCfg.TearingEffectPolarity = DSI_TE_RISING_EDGE;
  CmdCfg.HSPolarity = DSI_HSYNC_ACTIVE_HIGH;
  CmdCfg.VSPolarity = DSI_VSYNC_ACTIVE_HIGH;
  CmdCfg.DEPolarity = DSI_DATA_ENABLE_ACTIVE_HIGH;
  CmdCfg.VSyncPol = DSI_VSYNC_RISING;
  CmdCfg.AutomaticRefresh = DSI_AR_DISABLE;
  CmdCfg.TEAcknowledgeRequest = DSI_TE_ACKNOWLEDGE_ENABLE;
  if (HAL_DSI_ConfigAdaptedCommandMode(&hdsi, &CmdCfg) != HAL_OK)
  {
    Error_Handler();
  }
  if (HAL_DSI_SetGenericVCID(&hdsi, 0) != HAL_OK)
  {
    Error_Handler();
  }

}

static void MX_LTDC_Init(void)
{

  LTDC_LayerCfgTypeDef pLayerCfg = {0};

  hltdc.Instance = LTDC;
  hltdc.Init.HSPolarity = LTDC_HSPOLARITY_AH;
  hltdc.Init.VSPolarity = LTDC_VSPOLARITY_AH;
  hltdc.Init.DEPolarity = LTDC_DEPOLARITY_AL;
  hltdc.Init.PCPolarity = LTDC_PCPOLARITY_IPC;
  hltdc.Init.HorizontalSync = 0;
  hltdc.Init.VerticalSync = 0;
  hltdc.Init.AccumulatedHBP = 2;
  hltdc.Init.AccumulatedVBP = 2;
  hltdc.Init.AccumulatedActiveW = 802;
  hltdc.Init.AccumulatedActiveH = 482;
  hltdc.Init.TotalWidth = 803;
  hltdc.Init.TotalHeigh = 483;
  hltdc.Init.Backcolor.Blue = 0;
  hltdc.Init.Backcolor.Green = 0;
  hltdc.Init.Backcolor.Red = 0;
  if (HAL_LTDC_Init(&hltdc) != HAL_OK)
  {
    Error_Handler();
  }
  pLayerCfg.WindowX0 = 0;
  pLayerCfg.WindowX1 = 800;
  pLayerCfg.WindowY0 = 0;
  pLayerCfg.WindowY1 = 480;
  pLayerCfg.PixelFormat = LTDC_PIXEL_FORMAT_RGB565;
  pLayerCfg.Alpha = 255;
  pLayerCfg.Alpha0 = 0;
  pLayerCfg.BlendingFactor1 = LTDC_BLENDING_FACTOR1_PAxCA;
  pLayerCfg.BlendingFactor2 = LTDC_BLENDING_FACTOR2_PAxCA;
  pLayerCfg.FBStartAdress = 0xD0000000;
  pLayerCfg.ImageWidth = 800;
  pLayerCfg.ImageHeight = 480;
  pLayerCfg.Backcolor.Blue = 20;
  pLayerCfg.Backcolor.Green = 40;
  pLayerCfg.Backcolor.Red = 60;
  if (HAL_LTDC_ConfigLayer(&hltdc, &pLayerCfg, 0) != HAL_OK)
  {
    Error_Handler();
  }

}

static void MX_QUADSPI_Init(void)
{

  /* QUADSPI parameter configuration*/
  hqspi.Instance = QUADSPI;
  hqspi.Init.ClockPrescaler = 3;
  hqspi.Init.FifoThreshold = 1;
  hqspi.Init.SampleShifting = QSPI_SAMPLE_SHIFTING_NONE;
  hqspi.Init.FlashSize = 1;
  hqspi.Init.ChipSelectHighTime = QSPI_CS_HIGH_TIME_1_CYCLE;
  hqspi.Init.ClockMode = QSPI_CLOCK_MODE_0;
  hqspi.Init.DualFlash = QSPI_DUALFLASH_ENABLE;
  if (HAL_QSPI_Init(&hqspi) != HAL_OK)
  {
    Error_Handler();
  }

}

static void MX_RTC_Init(void)
{

  /** Initialize RTC Only
  */
  hrtc.Instance = RTC;
  hrtc.Init.HourFormat = RTC_HOURFORMAT_24;
  hrtc.Init.AsynchPrediv = 127;
  hrtc.Init.SynchPrediv = 255;
  hrtc.Init.OutPut = RTC_OUTPUT_DISABLE;
  hrtc.Init.OutPutPolarity = RTC_OUTPUT_POLARITY_HIGH;
  hrtc.Init.OutPutType = RTC_OUTPUT_TYPE_OPENDRAIN;
  hrtc.Init.OutPutRemap = RTC_OUTPUT_REMAP_NONE;
  if (HAL_RTC_Init(&hrtc) != HAL_OK)
  {
    Error_Handler();
  }

}

static void MX_TIM2_Init(void)
{

  TIM_ClockConfigTypeDef sClockSourceConfig = {0};
  TIM_MasterConfigTypeDef sMasterConfig = {0};

  htim2.Instance = TIM2;
  htim2.Init.Prescaler = 1000;
  htim2.Init.CounterMode = TIM_COUNTERMODE_UP;
  htim2.Init.Period = 72;
  htim2.Init.ClockDivision = TIM_CLOCKDIVISION_DIV1;
  htim2.Init.AutoReloadPreload = TIM_AUTORELOAD_PRELOAD_ENABLE;
  if (HAL_TIM_Base_Init(&htim2) != HAL_OK)
  {
    Error_Handler();
  }
  sClockSourceConfig.ClockSource = TIM_CLOCKSOURCE_INTERNAL;
  if (HAL_TIM_ConfigClockSource(&htim2, &sClockSourceConfig) != HAL_OK)
  {
    Error_Handler();
  }
  sMasterConfig.MasterOutputTrigger = TIM_TRGO_RESET;
  sMasterConfig.MasterSlaveMode = TIM_MASTERSLAVEMODE_DISABLE;
  if (HAL_TIMEx_MasterConfigSynchronization(&htim2, &sMasterConfig) != HAL_OK)
  {
    Error_Handler();
  }

}

static void MX_DMA_Init(void)
{

  /* DMA controller clock enable */
  __HAL_RCC_DMA2_CLK_ENABLE();

  /* Configure DMA request hdma_memtomem_dma2_stream0 on DMA2_Stream0 */
  hdma_memtomem_dma2_stream0.Instance = DMA2_Stream0;
  hdma_memtomem_dma2_stream0.Init.Request = DMA_REQUEST_MEM2MEM;
  hdma_memtomem_dma2_stream0.Init.Direction = DMA_MEMORY_TO_MEMORY;
  hdma_memtomem_dma2_stream0.Init.PeriphInc = DMA_PINC_ENABLE;
  hdma_memtomem_dma2_stream0.Init.MemInc = DMA_MINC_ENABLE;
  hdma_memtomem_dma2_stream0.Init.PeriphDataAlignment = DMA_PDATAALIGN_HALFWORD;
  hdma_memtomem_dma2_stream0.Init.MemDataAlignment = DMA_MDATAALIGN_HALFWORD;
  hdma_memtomem_dma2_stream0.Init.Mode = DMA_NORMAL;
  hdma_memtomem_dma2_stream0.Init.Priority = DMA_PRIORITY_HIGH;
  hdma_memtomem_dma2_stream0.Init.FIFOMode = DMA_FIFOMODE_ENABLE;
  hdma_memtomem_dma2_stream0.Init.FIFOThreshold = DMA_FIFO_THRESHOLD_1QUARTERFULL;
  hdma_memtomem_dma2_stream0.Init.MemBurst = DMA_MBURST_SINGLE;
  hdma_memtomem_dma2_stream0.Init.PeriphBurst = DMA_PBURST_SINGLE;
  if (HAL_DMA_Init(&hdma_memtomem_dma2_stream0) != HAL_OK)
  {
    Error_Handler( );
  }

}

/* FMC initialization function */
void MX_FMC_Init(void)
{

  FMC_SDRAM_TimingTypeDef SdramTiming = {0};

  /** Perform the SDRAM1 memory initialization sequence
  */
  hsdram1.Instance = FMC_SDRAM_DEVICE;
  /* hsdram1.Init */
  hsdram1.Init.SDBank = FMC_SDRAM_BANK2;
  hsdram1.Init.ColumnBitsNumber = FMC_SDRAM_COLUMN_BITS_NUM_8;
  hsdram1.Init.RowBitsNumber = FMC_SDRAM_ROW_BITS_NUM_11;
  hsdram1.Init.MemoryDataWidth = FMC_SDRAM_MEM_BUS_WIDTH_32;
  hsdram1.Init.InternalBankNumber = FMC_SDRAM_INTERN_BANKS_NUM_4;
  hsdram1.Init.CASLatency = FMC_SDRAM_CAS_LATENCY_1;
  hsdram1.Init.WriteProtection = FMC_SDRAM_WRITE_PROTECTION_DISABLE;
  hsdram1.Init.SDClockPeriod = FMC_SDRAM_CLOCK_DISABLE;
  hsdram1.Init.ReadBurst = FMC_SDRAM_RBURST_DISABLE;
  hsdram1.Init.ReadPipeDelay = FMC_SDRAM_RPIPE_DELAY_0;
  /* SdramTiming */
  SdramTiming.LoadToActiveDelay = 16;
  SdramTiming.ExitSelfRefreshDelay = 16;
  SdramTiming.SelfRefreshTime = 16;
  SdramTiming.RowCycleDelay = 16;
  SdramTiming.WriteRecoveryTime = 16;
  SdramTiming.RPDelay = 16;
  SdramTiming.RCDDelay = 16;

  if (HAL_SDRAM_Init(&hsdram1, &SdramTiming) != HAL_OK)
  {
    Error_Handler( );
  }

}

static void MX_GPIO_Init(void)
{
  GPIO_InitTypeDef GPIO_InitStruct = {0};

  /* GPIO Ports Clock Enable */
  __HAL_RCC_GPIOI_CLK_ENABLE();
  __HAL_RCC_GPIOG_CLK_ENABLE();
  __HAL_RCC_GPIOD_CLK_ENABLE();
  __HAL_RCC_GPIOA_CLK_ENABLE();
  __HAL_RCC_GPIOE_CLK_ENABLE();
  __HAL_RCC_GPIOH_CLK_ENABLE();
  __HAL_RCC_GPIOC_CLK_ENABLE();
  __HAL_RCC_GPIOF_CLK_ENABLE();
  __HAL_RCC_GPIOB_CLK_ENABLE();

  /*Configure GPIO pin : MCO1_Pin */
  GPIO_InitStruct.Pin = MCO1_Pin;
  GPIO_InitStruct.Mode = GPIO_MODE_AF_PP;
  GPIO_InitStruct.Pull = GPIO_NOPULL;
  GPIO_InitStruct.Speed = GPIO_SPEED_FREQ_LOW;
  GPIO_InitStruct.Alternate = GPIO_AF0_MCO;
  HAL_GPIO_Init(MCO1_GPIO_Port, &GPIO_InitStruct);

}

/* USER CODE BEGIN 4 */
void HAL_TIM_PeriodElapsedCallback(TIM_HandleTypeDef* htim)
{
    lv_tick_inc(1);
}
/* USER CODE END 4 */

void Error_Handler(void)
{
  __disable_irq();
  while (1)
  {
  }
}

/************************ (C) COPYRIGHT STMicroelectronics *****END OF FILE****/
